# apollo3p register map
Vendor: Ambiq Micro; Series: Apollo; File version: 1.0
CPU: CM4 r1p0, little endian, MPU, FPU, I-cache, D-cache, VTOR, ITCM, DTCM, 3 interrupt priority bits, 0 interrupts
Registers are 32-bit, read-write, reset 0x0 unless marked. A register's access mark holds for its fields unless they carry their own. Offsets are from the block's base; [hi:lo] are bit positions; 'fields as' and 'values as' point back to an identical list.

## CLKGEN — Clock Generator
Base 0x40004000
0x00 CALXT — This is the XT Oscillator Calibration value. This value allows any derived XT clocks to be calibrated. This means that the original 32KHz version of XT will not be changed, but a 16KHz version (divided down version) can be modified. This register value will add or subtract the number of cycles programmed in this register across a 32 seconds interval. For example, if a value of 100 is programmed in this register, then 100 additional clock cycles will be added into a 16KHz clock period across a 32 second interval.
  [10:0] CALXT — XT Oscillator calibration value. This register will enable the hardware to increase or decrease the number of cycles in a 16KHz clock derived from the original 32KHz version. The most significant bit is the sign. A '1' is a reduction, and a '0' is an addition. This calibration value will add or reduce the number of cycles programmed here across a 32 second interval. The maximum value that is effective is from -1024 to 1023.
0x04 CALRC — This is the LFRC Calibration value. Similar to the XT calibration, it allows the derived LFRC clock to be calibrated. The original 1024Hz clock source will not change, but a 512Hz version (divided down version) can be modified. This register will add or subtract the number of cycles programmed in this register across a 1024 seconds interval. For example, if a value of 200 is programmed in this register, then 200 additional clocks will be added into the 512Hz derived clock across a 1024 seconds interval.
  [17:0] CALRC — LFRC Oscillator calibration value. This register will enable the hardware to increase or decrease the number of cycles in a 512 Hz clock derived from the original 1024 version. The most significant bit is the sign. A '1' is a reduction, and a '0' is an addition. This calibration value will add or reduce the number of cycles programmed here across a 32 second interval. The range is from -131072 (decimal) to 131071 (decimal). This register is normally used in conjunction with ACALCTR register. The CALRC register will load the ACALCTR register (bits 17:0) if the ACALCTR register is set to measure the LFRC with the XT clock.
0x08 ACALCTR — This register can be used for 2 purposes. The first is to calibrate the LFRC clock using the XT clock source. The second is to measure an internal clock signal relative to the external clock. In that case, the ACALCTR will show the multiple of the external clock with respect to the internal clock signal. E.g. Fref = Fmeas x ACALCTR. Note that this register should not be confused with the HFRC Adjustment register, which is separately defined in CLKGEN_HFADJ register.
  [23:0] ACALCTR — Autocalibration Counter result. Bits 17 down to 0 of this is feed directly to the CALRC register if ACAL register in OCTRL register is set to 1024SEC or 512SEC.
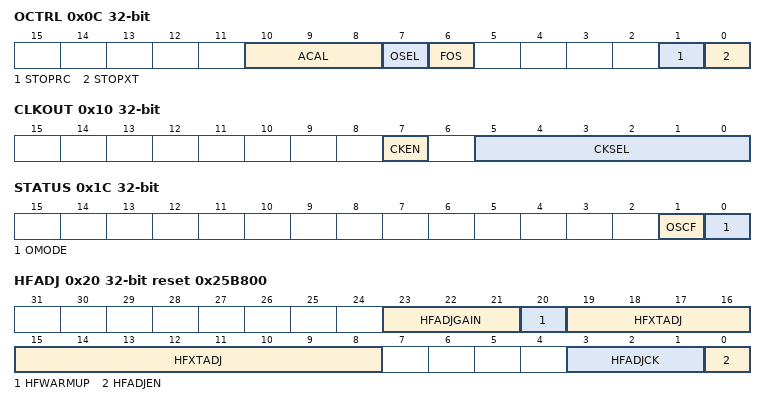
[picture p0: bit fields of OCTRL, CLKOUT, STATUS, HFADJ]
0x0C OCTRL — This register includes controls for autocalibration in addition to the RTC oscillator controls.
  [10:8] ACAL — Autocalibration control. This selects the source to be used in the autocalibration flow. This flow can also be used to measure an internal clock against an external clock source, with the external clock normally used as the reference.
    0=DIS (Disable Autocalibration); 2=1024SEC (Autocalibrate every 1024 seconds. Once autocalibration is done, an interrupt will be triggered at the end of 1024 seconds.); 3=512SEC (Autocalibrate every 512 seconds. Once autocalibration is done, an interrupt will be trigged at the end of 512 seconds.); 6=XTFREQ (Frequency measurement using XT. The XT clock is normally considered much more accurate than the LFRC clock source.); 7=EXTFREQ (Frequency measurement using external clock.)
  [7] OSEL — Selects the RTC oscillator (1 => LFRC, 0 => XT)
    0=RTC_XT (RTC uses the XT); 1=RTC_LFRC (RTC uses the LFRC)
  [6] FOS — Oscillator switch on failure function. If this is set, then LFRC clock source will switch from XT to RC.
    0=DIS (Disable the oscillator switch on failure function.); 1=EN (Enable the oscillator switch on failure function.)
  [1] STOPRC — Stop the LFRC Oscillator to the RTC
    0=EN (Enable the LFRC Oscillator to drive the RTC); 1=STOP (Stop the LFRC Oscillator when driving the RTC)
  [0] STOPXT — Stop the XT Oscillator to the RTC
    0=EN (Enable the XT Oscillator to drive the RTC); 1=STOP (Stop the XT Oscillator when driving the RTC)
0x10 CLKOUT — This register enables the CLKOUT to the GPIOs, and selects the clock source to that.
  [7] CKEN — Enable the CLKOUT signal
    0=DIS (Disable CLKOUT); 1=EN (Enable CLKOUT)
  [5:0] CKSEL — CLKOUT signal select
    0=LFRC (LFRC Low Frequency RC); 1=XT_DIV2 (XT / 2); 2=XT_DIV4 (XT / 4); 3=XT_DIV8 (XT / 8); 4=XT_DIV16 (XT / 16); 5=XT_DIV32 (XT / 32); 16=RTC_1Hz (1 Hz as selected in RTC); 22=XT_DIV2M (XT / 2^21); 23=XT (Crystal); 24=CG_100Hz (100 Hz as selected in CLKGEN); 25=HFRC (High Frequency RC); 26=HFRC_DIV4 (HFRC / 4); 27=HFRC_DIV8 (HFRC / 8); 28=HFRC_DIV16 (HFRC / 16); 29=HFRC_DIV64 (HFRC / 64); 30=HFRC_DIV128 (HFRC / 128); 31=HFRC_DIV256 (HFRC / 256); 32=HFRC_DIV512 (HFRC / 512); 34=FLASH_CLK (Flash Clock); 35=LFRC_DIV2 (LFRC / 2); 36=LFRC_DIV32 (LFRC / 32); 37=LFRC_DIV512 (LFRC / 512); 38=LFRC_DIV32K (LFRC / 32768); 39=XT_DIV256 (XT / 256); 40=XT_DIV8K (XT / 8192); 41=XT_DIV64K (XT / 2^16); 42=ULFRC_DIV16 (Uncal LFRC / 16); 43=ULFRC_DIV128 (Uncal LFRC / 128); 44=ULFRC_1Hz (Uncal LFRC / 1024); 45=ULFRC_DIV4K (Uncal LFRC / 4096); 46=ULFRC_DIV1M (Uncal LFRC / 2^20); 47=HFRC_DIV64K (HFRC / 2^16); 48=HFRC_DIV16M (HFRC / 2^24); 49=LFRC_DIV1M (LFRC / 2^20); 50=HFRCNE (HFRC (not autoenabled)); 51=HFRCNE_DIV8 (HFRC / 8 (not autoenabled)); 53=XTNE (XT (not autoenabled)); 54=XTNE_DIV16 (XT / 16 (not autoenabled)); 55=LFRCNE_DIV32 (LFRC / 32 (not autoenabled)); 57=LFRCNE (LFRC (not autoenabled) - Default for undefined values)
0x14 CLKKEY — This controls the write access to the CCTRL register. This prevents customers from accidentally setting the HFRC clocks to be half of what they are set to.
  [31:0] CLKKEY — Key register value.
    71=Key (Key value to unlock the register.)
0x18 CCTRL reset 0x1 — This register controls the main divider for HFRC clock. If this is set, all internal HFRC clock sources are divided by 2.
  [0] CORESEL — Core Clock divisor
    0=HFRC (Core Clock is HFRC); 1=HFRC_DIV2 (Core Clock is HFRC / 2)
0x1C STATUS — This register provides status to the XT oscillator and the source of the RTC.
  [1] OSCF — XT Oscillator is enabled but not oscillating
  [0] OMODE — Current RTC oscillator (1 => LFRC, 0 => XT). After an RTC oscillator change, it may take up to 2 seconds for this field to reflect the new oscillator.
0x20 HFADJ reset 0x25B800 — This register controls the HFRC adjustment. The HFRC clock can change with temperature and process corners, and this register controls the HFRC adjustment logic which reduces the fluctuations to the clock.
  [23:21] HFADJGAIN — Gain control for HFRC adjustment
    0=Gain_of_1 (HF Adjust with Gain of 1); 1=Gain_of_1_in_2 (HF Adjust with Gain of 0.5); 2=Gain_of_1_in_4 (HF Adjust with Gain of 0.25); 3=Gain_of_1_in_8 (HF Adjust with Gain of 0.125); 4=Gain_of_1_in_16 (HF Adjust with Gain of 0.0625); 5=Gain_of_1_in_32 (HF Adjust with Gain of 0.03125)
  [20] HFWARMUP — XT warm-up period for HFRC adjustment
    0=1SEC (Autoadjust XT warm-up period = 1-2 seconds); 1=2SEC (Autoadjust XT warm-up period = 2-4 seconds)
  [19:8] HFXTADJ — Target HFRC adjustment value.
  [3:1] HFADJCK — Repeat period for HFRC adjustment
    0=4SEC (Autoadjust repeat period = 4 seconds); 1=16SEC (Autoadjust repeat period = 16 seconds); 2=32SEC (Autoadjust repeat period = 32 seconds); 3=64SEC (Autoadjust repeat period = 64 seconds); 4=128SEC (Autoadjust repeat period = 128 seconds); 5=256SEC (Autoadjust repeat period = 256 seconds); 6=512SEC (Autoadjust repeat period = 512 seconds); 7=1024SEC (Autoadjust repeat period = 1024 seconds)
  [0] HFADJEN — HFRC adjustment control
    0=DIS (Disable the HFRC adjustment); 1=EN (Enable the HFRC adjustment)
0x28 CLOCKENSTAT — This register provides the enable status to all the peripheral clocks.
  [31:0] CLOCKENSTAT — Clock enable status
    1=ADC_CLKEN (Clock enable for the ADC.); 2=APBDMA_ACTIVITY_CLKEN (Clock enable for the APBDMA ACTIVITY); 4=APBDMA_AOH_CLKEN (Clock enable for the APBDMA AOH DOMAIN); 8=APBDMA_AOL_CLKEN (Clock enable for the APBDMA AOL DOMAIN); 16=APBDMA_APB_CLKEN (Clock enable for the APBDMA_APB); 32=APBDMA_BLEL_CLKEN (Clock enable for the APBDMA_BLEL); 64=APBDMA_HCPA_CLKEN (Clock enable for the APBDMA_HCPA); 128=APBDMA_HCPB_CLKEN (Clock enable for the APBDMA_HCPB); 0x100=APBDMA_HCPC_CLKEN (Clock enable for the APBDMA_HCPC); 0x200=APBDMA_MSPI_CLKEN (Clock enable for the APBDMA_MSPI); 0x400=APBDMA_MSPI1_CLKEN (Clock enable for the APBDMA_MSPI1); 0x800=APBDMA_MSPI2_CLKEN (Clock enable for the APBDMA_MSPI2); 0x1000=APBDMA_PDM_CLKEN (Clock enable for the APBDMA_PDM); 0x2000=BLEIF_CLK_CLKEN (Clock enable for the BLEIF); 0x4000=BLEIF_CLK32K_CLKEN (Clock enable for the BLEIF 32khZ CLOCK); 0x8000=CTIMER_CLKEN (Clock enable for the CTIMER BLOCK); 0x10000=CTIMER0A_CLKEN (Clock enable for the CTIMER0A); 0x20000=CTIMER0B_CLKEN (Clock enable for the CTIMER0B); 0x40000=CTIMER1A_CLKEN (Clock enable for the CTIMER1A); 0x80000=CTIMER1B_CLKEN (Clock enable for the CTIMER1B); 0x100000=CTIMER2A_CLKEN (Clock enable for the CTIMER2A); 0x200000=CTIMER2B_CLKEN (Clock enable for the CTIMER2B); 0x400000=CTIMER3A_CLKEN (Clock enable for the CTIMER3A); 0x800000=CTIMER3B_CLKEN (Clock enable for the CTIMER3B); 0x1000000=CTIMER4A_CLKEN (Clock enable for the CTIMER4A); 0x2000000=CTIMER4B_CLKEN (Clock enable for the CTIMER4B); 0x4000000=CTIMER5A_CLKEN (Clock enable for the CTIMER5A); 0x8000000=CTIMER5B_CLKEN (Clock enable for the CTIMER5B); 0x10000000=CTIMER6A_CLKEN (Clock enable for the CTIMER6A); 0x20000000=CTIMER6B_CLKEN (Clock enable for the CTIMER6B); 0x40000000=CTIMER7A_CLKEN (Clock enable for the CTIMER7A); 0x80000000=CTIMER7B_CLKEN (Clock enable for the CTIMER7B)
0x2C CLOCKEN2STAT — This is a continuation of the clock enable status.
  [31:0] CLOCKEN2STAT — Clock enable status 2
    1=DAP_CLKEN (Clock enable for the DAP); 2=IOMSTRIFC0_CLKEN (Clock enable for the IO MASTER 0 IFC INTERFACE); 4=IOMSTRIFC1_CLKEN (Clock enable for the IO MASTER 1 IFC INTERFACE); 8=IOMSTRIFC2_CLKEN (Clock enable for the IO MASTER 2 IFC INTERFACE); 16=IOMSTRIFC3_CLKEN (Clock enable for the IO MASTER 3 IFC INTERFACE); 32=IOMSTRIFC4_CLKEN (Clock enable for the IO MASTER 4 IFC INTERFACE); 64=IOMSTRIFC5_CLKEN (Clock enable for the IO MASTER 5 IFC INTERFACE); 128=PDM_CLKEN (Clock enable for the PDM); 0x100=PDMIFC_CLKEN (Clock enable for the PDM INTERFACE); 0x200=PWRCTRL_CLKEN (Clock enable for the PWRCTRL); 0x400=PWRCTRL_COUNT_CLKEN (Clock enable for the PWRCTRL counter); 0x800=RSTGEN_CLKEN (Clock enable for the RSTGEN); 0x1000=SCARD_CLKEN (Clock enable for the SCARD); 0x2000=SCARD_ALTAPB_CLKEN (Clock enable for the SCARD ALTAPB); 0x4000=STIMER_CNT_CLKEN (Clock enable for the STIMER_CNT_CLKEN); 0x8000=TPIU_CLKEN (Clock enable for the TPIU_CLKEN); 0x10000=UART0HF_CLKEN (Clock enable for the UART0 HF); 0x20000=UART1HF_CLKEN (Clock enable for the UART1 HF); 0x40000=WDT_CLKEN (Clock enable for the Watchdog timer); 0x40000000=XT_32KHZ_EN (Clock enable for the XT 32KHZ); 0x80000000=FORCEHFRC (HFRC is forced on Status.)
0x30 CLOCKEN3STAT — This is a continuation of the clock enable status.
  [31:0] CLOCKEN3STAT — Clock enable status 3
    0x20000=DAP_enabled (DAP clock is enabled [17]); 0x40000=VCOMP_enabled (VCOMP power-down indicator [18]); 0x1000000=XTAL_enabled (XTAL is enabled [24]); 0x2000000=HFRC_enabled (HFRC is enabled [25]); 0x4000000=HFADJEN (HFRC Adjust enabled [26]); 0x8000000=HFRC_en_out (HFRC Enabled out [27]); 0x10000000=RTC_XT (RTC use XT [28]); 0x20000000=clkout_xtal_en (XTAL clkout enabled [29]); 0x40000000=clkout_hfrc_en (HFRC clkout enabled [30]); 0x80000000=flashclk_en (Flash clk is enabled [31])
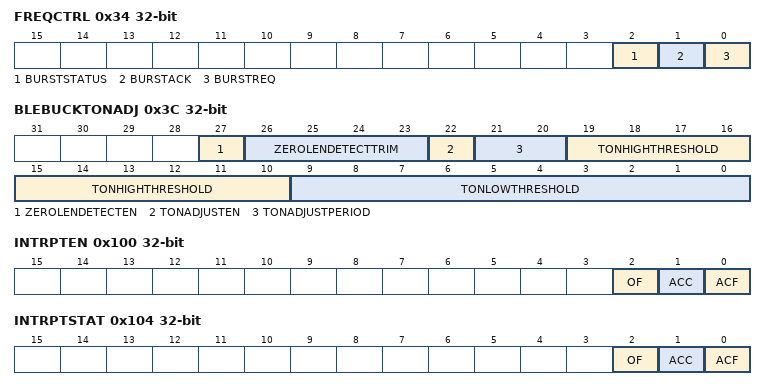
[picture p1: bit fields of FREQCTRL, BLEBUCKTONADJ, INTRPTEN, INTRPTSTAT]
0x34 FREQCTRL — This register provides the burst control and burst status.
  [2] BURSTSTATUS — This represents frequency burst status.
  [1] BURSTACK — Frequency Burst Request Acknowledge. Frequency burst requested is always acknowledged whether burst is granted or not depending on feature enable.
  [0] BURSTREQ — Frequency Burst Enable Request
    0=DIS (Frequency for ARM core stays at 48MHz); 1=EN (Frequency for ARM core is increased to 96MHz)
0x3C BLEBUCKTONADJ — This is the register control for BLE ton adjustment logic.
  [27] ZEROLENDETECTEN — BLEBUCK ZERO LENGTH DETECT ENABLE
    0=DIS (Disable Zero Length Detect); 1=EN (Enable Zero Length Detect)
  [26:23] ZEROLENDETECTTRIM — BLEBUCK ZERO LENGTH DETECT TRIM
    15=SetF (Indicator send when the BLE BUCK asserts blebuck_comp1 for about 81 us (10 percent margin of error) or more); 14=SetE (Indicator send when the BLE BUCK asserts blebuck_comp1 for about 75.6 us (10 percent margin of error) or more); 13=SetD (Indicator send when the BLE BUCK asserts blebuck_comp1 for about 70.2 us (10 percent margin of error) or more); 12=SetC (Indicator send when the BLE BUCK asserts blebuck_comp1 for about 64.8 us (10 percent margin of error) or more); 11=SetB (Indicator send when the BLE BUCK asserts blebuck_comp1 for about 59.4 us (10 percent margin of error) or more); 10=SetA (Indicator send when the BLE BUCK asserts blebuck_comp1 for about 54.0 us (10 percent margin of error) or more); 9=Set9 (Indicator send when the BLE BUCK asserts blebuck_comp1 for about 48.6 us (10 percent margin of error) or more); 8=Set8 (Indicator send when the BLE BUCK asserts blebuck_comp1 for about 43.2 us (10 percent margin of error) or more); 7=Set7 (Indicator send when the BLE BUCK asserts blebuck_comp1 for about 37.8 us (10 percent margin of error) or more); 6=Set6 (Indicator send when the BLE BUCK asserts blebuck_comp1 for about 32.4 us (10 percent margin of error) or more); 5=Set5 (Indicator send when the BLE BUCK asserts blebuck_comp1 for about 27.0 us (10 percent margin of error) or more); 4=Set4 (Indicator send when the BLE BUCK asserts blebuck_comp1 for about 21.6 us (10 percent margin of error) or more); 3=Set3 (Indicator send when the BLE BUCK asserts blebuck_comp1 for about 16.2 us (10 percent margin of error) or more); 2=Set2 (Indicator send when the BLE BUCK asserts blebuck_comp1 for about 10.8 us (10 percent margin of error) or more); 1=Set1 (Indicator send when the BLE BUCK asserts blebuck_comp1 for about 5.4 us (10 percent margin of error) or more); 0=Set0 (Indicator send when the BLE BUCK asserts blebuck_comp1 for about 2.0 us (10 percent margin of error) or more)
  [22] TONADJUSTEN — TON ADJUST ENABLE
    0=DIS (Disable Adjust for BLE BUCK TON trim); 1=EN (Enable Adjust for BLE BUCK TON trim)
  [21:20] TONADJUSTPERIOD
    3=HFRC_3KHz (Adjust done for every 1 3KHz period); 2=HFRC_12KHz (Adjust done for every 1 12KHz period); 1=HFRC_47KHz (Adjust done for every 1 47KHz period); 0=HFRC_94KHz (Adjust done for every 1 94KHz period)
  [19:10] TONHIGHTHRESHOLD — TON ADJUST HIGH THRESHOLD. Suggested values are #15(94KHz) #2A(47Khz) #A6(12Khz) #29A(3Khz)
  [9:0] TONLOWTHRESHOLD — TON ADJUST LOW THRESHOLD. Suggested values are #A(94KHz) #15(47KHz) #53(12Khz) #14D(3Khz)
0x100 INTRPTEN — Set bits in this register to allow this module to generate the corresponding interrupt.
  [2] OF — XT Oscillator Fail interrupt
  [1] ACC — Autocalibration Complete interrupt
  [0] ACF — Autocalibration Fail interrupt
0x104 INTRPTSTAT — Read bits from this register to discover the cause of a recent interrupt.
  fields as INTRPTEN
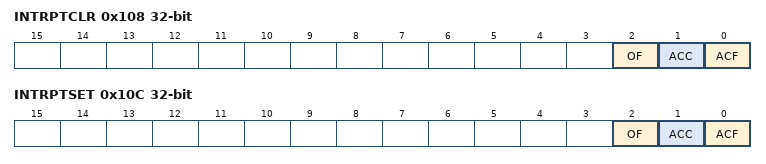
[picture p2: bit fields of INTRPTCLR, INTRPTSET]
0x108 INTRPTCLR — Write a 1 to a bit in this register to clear the interrupt status associated with that bit.
  fields as INTRPTEN
0x10C INTRPTSET — Write a 1 to a bit in this register to instantly generate an interrupt from this module. (Generally used for testing purposes).
  fields as INTRPTEN
